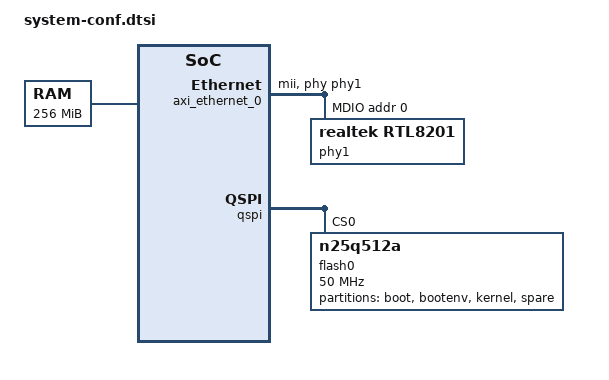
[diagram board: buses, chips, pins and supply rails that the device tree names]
/*
 * CAUTION: This file is automatically generated by PetaLinux SDK.
 * DO NOT modify this file
 */


/ {
	chosen {
		bootargs = "console=ttyPS0,115200 earlyprintk maxcpus=1 root=/dev/mmcblk0p2 rw rootwait";
		stdout-path = "serial0:115200n8";
	};
	
	aliases {
		ethernet0 = &axi_ethernet_0;
		serial0 = &uart0;
		spi0 = &qspi;
	};
	
	memory {
		device_type = "memory";
		
		/* AMP Mode, DDR Address Is Divided Into Two Pieces
		 * 0 ~ 0x10000000:          Cpu0
		 * 0x10000000 ~ 0x1FFFFFFF: Cpu1
		 */
		reg = <0x0 0x10000000>;
	};
};

&axi_ethernet_0 {
	local-mac-address = [00 0a 35 00 01 22];
	phy-handle = <&phy1>;
	xlnx,has-mdio = <0x1>;
	phy-mode = "mii";
	
	mdio {
	    #address-cells = <1>;
	    #size-cells = <0>;
	    
	    phy1: phy@1 {
	        compatible = "realtek,rtl8201", "ethernet-phy-id001c.c816";
	        device_type = "ethernet-phy";
	        reg = <0>;
	    };
	};
};

&qspi {
	#address-cells = <1>;
	#size-cells = <0>;
	flash0: flash@0 {
		compatible = "n25q512a","micron,m25p80";
		reg = <0x0>;
		#address-cells = <1>;
		#size-cells = <1>;
		spi-max-frequency = <50000000>;
		partition@0x00000000 {
			label = "boot";
			reg = <0x00000000 0x00500000>;
		};
		partition@0x00500000 {
			label = "bootenv";
			reg = <0x00500000 0x00020000>;
		};
		partition@0x00520000 {
			label = "kernel";
			reg = <0x00520000 0x00a80000>;
		};
		partition@0x00fa0000 {
			label = "spare";
			reg = <0x00fa0000 0x00000000>;
		};
	};
};

